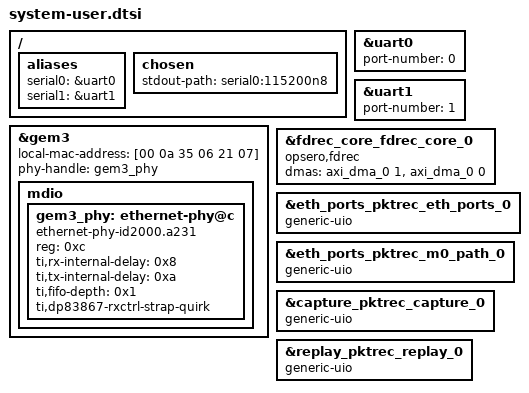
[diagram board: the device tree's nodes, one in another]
// SPDX-License-Identifier: MIT
// Copyright (C) 2025-2026, Opsero Electronic Design Inc.  All rights reserved.

/*
 * SoC-side board fixups, layered on top of the gen-machineconf /
 * lopper-generated cortexa53-linux.dts (which already carries the PS config
 * and the PL xilinx_xdma PCIe node from the XSA: one Gen3 x1 root port
 * (pcie_ssd1/xdma_0) for SSD slot 1 of the FPGA Drive FMC Gen4 on HPC1).
 *
 * UART (ttyPS console):
 *   The 2025.2 lopper/gen-machineconf flow emits port-number = <0> on BOTH
 *   uart0 (ff000000) and uart1 (ff010000), so the ttyPS0/ttyPS1 assignment is
 *   left to probe order. This board's console is on psu_uart_0, so pin the
 *   port numbers (and serial aliases) explicitly. Mirrors the PetaLinux BSPs.
 *
 * Note: unlike the ZCU104, this board's SD interface sustains UHS modes (the
 * PetaLinux BSP needs no sdhci cap), so no SD override is applied here.
 */

&uart0 {
   port-number = <0>;
};

&uart1 {
   port-number = <1>;
};

/ {
   aliases {
      serial0 = &uart0;
      serial1 = &uart1;
   };
   chosen {
      stdout-path = "serial0:115200n8";
   };
};

/* PS GEM3 (board RJ45): the SDT flow does not describe the board-level
 * TI DP83867 PHY, so Linux falls back to the Generic PHY driver and the
 * RGMII clock delays are never programmed - the link negotiates 1G but
 * passes no packets. Values from the official zynqmp-zcu106-revA.dts
 * (PHY at MDIO address 0xc). The fixed MAC replaces the random one the
 * SDT flow leaves us with, keeping DHCP leases stable across boots.
 */
&gem3 {
	local-mac-address = [00 0a 35 06 21 07];
	phy-handle = <&gem3_phy>;
	mdio {
		#address-cells = <1>;
		#size-cells = <0>;
		gem3_phy: ethernet-phy@c {
			compatible = "ethernet-phy-id2000.a231";
			reg = <0xc>;
			ti,rx-internal-delay = <0x8>;
			ti,tx-internal-delay = <0xa>;
			ti,fifo-depth = <0x1>;
			ti,dp83867-rxctrl-strap-quirk;
		};
	};
};

/*
 * FPGA Drive Recorder: bind the fdrec kernel driver (Yocto/meta-fdrec,
 * sw/fdrec-driver) to the fdrec_core register block.
 *
 * sdtgen emits the module-reference block from the XSA as
 *   fdrec_core_fdrec_core_0: fdrec_core@420010000 { compatible = "xlnx,fdrec-core-1.0";
 *                                                   reg = <0x4 0x20010000 0x0 0x1000>; ... }
 * and the AXI DMA as axi_dma_0 (SG, MM2S + S2MM, xlnx,sg-length-width = <26>,
 * xlnx,addrwidth = <0x40>, each channel's interrupt on its dma-channel child,
 * not dma-coherent: S_AXI_HP2_FPD; S2MM = SPI 95, MM2S = SPI 96). Keep the
 * generated reg; replace the
 * generic compatible and add both channels. xilinx_dma numbers the channels
 * of an AXI DMA 0 = MM2S, 1 = S2MM (of_dma_xilinx_xlate), so:
 *   "rx" (record,   S2MM) = <&axi_dma_0 1>
 *   "tx" (playback, MM2S) = <&axi_dma_0 0>  (optional for the driver: without
 *                                            it, record only)
 * If the block design cells are renamed, these labels change with them
 * (Vivado/src/bd/bd_zynqmp.tcl keeps fdrec_core/fdrec_core_0 and axi_dma_0).
 */
&fdrec_core_fdrec_core_0 {
   compatible = "opsero,fdrec";
   dmas = <&axi_dma_0 1>, <&axi_dma_0 0>;
   dma-names = "rx", "tx";
};

/*
 * Ethernet FMC Max (OP080) port subsystem (block-design hierarchy eth_ports):
 * expose both register blocks to user space through generic-uio for pktrec-phy
 * (sw/pktrec-tools, Yocto/meta-pktrec). boot.scr already passes
 * uio_pdrv_genirq.of_id=generic-uio; meta-pktrec builds the driver in.
 *   eth_ports_pktrec_eth_ports_0  0x4_2008_0000 512K  MAC/PCS regs, MDIO, GT APB
 *   eth_ports_pktrec_m0_path_0    0x4_2002_0000   4K  M0 path regs
 * No interrupts. The labels follow the block-design cell paths.
 */
&eth_ports_pktrec_eth_ports_0 {
   compatible = "generic-uio";
};

&eth_ports_pktrec_m0_path_0 {
   compatible = "generic-uio";
};

/*
 * Capture path (block-design hierarchy capture, M1): capture control, per-port
 * counters, record merge statistics and the shared timebase, for pktrec-cap
 * (sw/pktrec-apps), which finds the UIO device by its address.
 *   capture_pktrec_capture_0      0x4_2003_0000   4K  include/pktrec_regs.h PKTREC_CAP_*
 */
&capture_pktrec_capture_0 {
   compatible = "generic-uio";
};

/*
 * Replay (block-design hierarchy replay, M6): record parser, frame store and
 * scheduler, for pktrec-replay (sw/pktrec-apps), which finds the UIO device by
 * its address.
 *   replay_pktrec_replay_0        0x4_2004_0000   4K  include/pktrec_regs.h PKTREC_RPL_*
 */
&replay_pktrec_replay_0 {
   compatible = "generic-uio";
};
